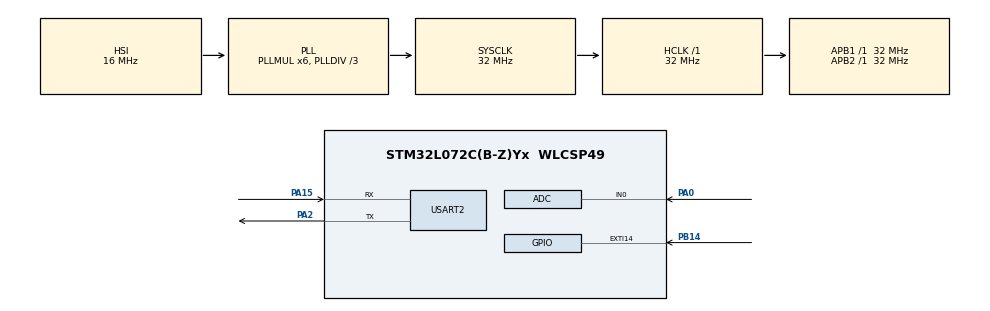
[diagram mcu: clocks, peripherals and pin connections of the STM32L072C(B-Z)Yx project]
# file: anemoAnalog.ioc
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ADC.ContinuousConvMode=ENABLE
ADC.SamplingTime=ADC_SAMPLETIME_79CYCLES_5
Dma.ADC.0.Direction=DMA_PERIPH_TO_MEMORY
Dma.ADC.0.Instance=DMA1_Channel1
Dma.ADC.0.MemDataAlignment=DMA_MDATAALIGN_HALFWORD
Dma.ADC.0.MemInc=DMA_MINC_ENABLE
Dma.ADC.0.Mode=DMA_CIRCULAR
Dma.ADC.0.PeriphDataAlignment=DMA_PDATAALIGN_HALFWORD
Dma.ADC.0.PeriphInc=DMA_PINC_DISABLE
Dma.ADC.0.Priority=DMA_PRIORITY_LOW
Dma.Request0=ADC
Mcu.Family=STM32L0
Mcu.Name=STM32L072C(B-Z)Yx
Mcu.Package=WLCSP49
NVIC.DMA1_Channel1_IRQn=true\:0\:0\:false\:false\:true\:false\:true\:true
NVIC.EXTI4_15_IRQn=true\:0\:0\:false\:false\:true\:true\:true\:true
PA0.Mode=IN0
PA0.Signal=ADC_IN0
PA15.GPIO_Speed=GPIO_SPEED_FREQ_HIGH
PA15.Mode=Asynchronous
PA15.Signal=USART2_RX
PA2.GPIO_Speed=GPIO_SPEED_FREQ_HIGH
PA2.Mode=Asynchronous
PA2.Signal=USART2_TX
PB14.GPIO_ModeDefaultEXTI=GPIO_MODE_IT_RISING_FALLING
PB14.Signal=GPXTI14
ProjectManager.HeapSize=0x200
ProjectManager.StackSize=0x400
ProjectManager.TargetToolchain=STM32CubeIDE
RCC.AHBFreq_Value=32000000
RCC.APB1Freq_Value=32000000
RCC.APB1TimFreq_Value=32000000
RCC.APB2Freq_Value=32000000
RCC.APB2TimFreq_Value=32000000
RCC.HCLKFreq_Value=32000000
RCC.HSE_VALUE=8000000
RCC.HSI16_VALUE=16000000
RCC.HSI48_VALUE=48000000
RCC.HSI_VALUE=16000000
RCC.LSE_VALUE=32768
RCC.MSI_VALUE=2097000
RCC.PLLDIV=RCC_PLLDIV_3
RCC.PLLMUL=RCC_PLLMUL_6
RCC.SYSCLKFreq_VALUE=32000000
RCC.SYSCLKSource=RCC_SYSCLKSOURCE_PLLCLK
RCC.VCOOutputFreq_Value=96000000
USART2.VirtualMode-Asynchronous=VM_ASYNC
board=B-L072Z-LRWAN1

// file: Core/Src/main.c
/* USER CODE BEGIN Header */
/**
  ******************************************************************************
  * @file           : main.c
  * @brief          : Main program body
  ******************************************************************************
  * @attention
  *
  * Copyright (c) 2024 STMicroelectronics.
  * All rights reserved.
  *
  * This software is licensed under terms that can be found in the LICENSE file
  * in the root directory of this software component.
  * If no LICENSE file comes with this software, it is provided AS-IS.
  *
  ******************************************************************************
  */
/* USER CODE END Header */
#include "main.h"
#include "stdio.h"

ADC_HandleTypeDef hadc;
DMA_HandleTypeDef hdma_adc;

UART_HandleTypeDef huart2;

/* USER CODE BEGIN PV */
uint32_t direction;

char readval[150];

/* USER CODE END PV */

void SystemClock_Config(void);
static void MX_GPIO_Init(void);
static void MX_DMA_Init(void);
static void MX_ADC_Init(void);
static void MX_USART2_UART_Init(void);

int main(void)
{

  /* MCU Configuration--------------------------------------------------------*/

  /* Reset of all peripherals, Initializes the Flash interface and the Systick. */
  HAL_Init();

  /* Configure the system clock */
  SystemClock_Config();

  /* Initialize all configured peripherals */
  MX_GPIO_Init();
  MX_DMA_Init();
  MX_ADC_Init();
  MX_USART2_UART_Init();
  /* USER CODE BEGIN 2 */
HAL_ADCEx_Calibration_Start(&hadc, ADC_SINGLE_ENDED);
HAL_ADC_Start_DMA(&hadc,(uint32_t*)&direction,1);
  /* USER CODE END 2 */

  /* Infinite loop */
  /* USER CODE BEGIN WHILE */
  while (1)
  {   HAL_ADC_Start(&hadc);
	  HAL_ADC_PollForConversion(&hadc,1000);
	  	direction= HAL_ADC_GetValue(&hadc);
	  	sprintf(readval,"val: %lu\r\n",direction);
	  	HAL_UART_Transmit(&huart2,(uint8_t *)readval,sizeof(readval),HAL_MAX_DELAY);
	  	HAL_Delay(1000);

    /* USER CODE END WHILE */

  }
}

void SystemClock_Config(void)
{
  RCC_OscInitTypeDef RCC_OscInitStruct = {0};
  RCC_ClkInitTypeDef RCC_ClkInitStruct = {0};
  RCC_PeriphCLKInitTypeDef PeriphClkInit = {0};

  /** Configure the main internal regulator output voltage
  */
  __HAL_PWR_VOLTAGESCALING_CONFIG(PWR_REGULATOR_VOLTAGE_SCALE1);

  /** Initializes the RCC Oscillators according to the specified parameters
  * in the RCC_OscInitTypeDef structure.
  */
  RCC_OscInitStruct.OscillatorType = RCC_OSCILLATORTYPE_HSI;
  RCC_OscInitStruct.HSIState = RCC_HSI_ON;
  RCC_OscInitStruct.HSICalibrationValue = RCC_HSICALIBRATION_DEFAULT;
  RCC_OscInitStruct.PLL.PLLState = RCC_PLL_ON;
  RCC_OscInitStruct.PLL.PLLSource = RCC_PLLSOURCE_HSI;
  RCC_OscInitStruct.PLL.PLLMUL = RCC_PLLMUL_6;
  RCC_OscInitStruct.PLL.PLLDIV = RCC_PLLDIV_3;
  if (HAL_RCC_OscConfig(&RCC_OscInitStruct) != HAL_OK)
  {
    Error_Handler();
  }

  /** Initializes the CPU, AHB and APB buses clocks
  */
  RCC_ClkInitStruct.ClockType = RCC_CLOCKTYPE_HCLK|RCC_CLOCKTYPE_SYSCLK
                              |RCC_CLOCKTYPE_PCLK1|RCC_CLOCKTYPE_PCLK2;
  RCC_ClkInitStruct.SYSCLKSource = RCC_SYSCLKSOURCE_PLLCLK;
  RCC_ClkInitStruct.AHBCLKDivider = RCC_SYSCLK_DIV1;
  RCC_ClkInitStruct.APB1CLKDivider = RCC_HCLK_DIV1;
  RCC_ClkInitStruct.APB2CLKDivider = RCC_HCLK_DIV1;

  if (HAL_RCC_ClockConfig(&RCC_ClkInitStruct, FLASH_LATENCY_1) != HAL_OK)
  {
    Error_Handler();
  }
  PeriphClkInit.PeriphClockSelection = RCC_PERIPHCLK_USART2;
  PeriphClkInit.Usart2ClockSelection = RCC_USART2CLKSOURCE_PCLK1;
  if (HAL_RCCEx_PeriphCLKConfig(&PeriphClkInit) != HAL_OK)
  {
    Error_Handler();
  }
}

static void MX_ADC_Init(void)
{

  ADC_ChannelConfTypeDef sConfig = {0};

  /** Configure the global features of the ADC (Clock, Resolution, Data Alignment and number of conversion)
  */
  hadc.Instance = ADC1;
  hadc.Init.OversamplingMode = DISABLE;
  hadc.Init.ClockPrescaler = ADC_CLOCK_SYNC_PCLK_DIV2;
  hadc.Init.Resolution = ADC_RESOLUTION_12B;
  hadc.Init.SamplingTime = ADC_SAMPLETIME_79CYCLES_5;
  hadc.Init.ScanConvMode = ADC_SCAN_DIRECTION_FORWARD;
  hadc.Init.DataAlign = ADC_DATAALIGN_RIGHT;
  hadc.Init.ContinuousConvMode = ENABLE;
  hadc.Init.DiscontinuousConvMode = DISABLE;
  hadc.Init.ExternalTrigConvEdge = ADC_EXTERNALTRIGCONVEDGE_NONE;
  hadc.Init.ExternalTrigConv = ADC_SOFTWARE_START;
  hadc.Init.DMAContinuousRequests = DISABLE;
  hadc.Init.EOCSelection = ADC_EOC_SINGLE_CONV;
  hadc.Init.Overrun = ADC_OVR_DATA_PRESERVED;
  hadc.Init.LowPowerAutoWait = DISABLE;
  hadc.Init.LowPowerFrequencyMode = DISABLE;
  hadc.Init.LowPowerAutoPowerOff = DISABLE;
  if (HAL_ADC_Init(&hadc) != HAL_OK)
  {
    Error_Handler();
  }

  /** Configure for the selected ADC regular channel to be converted.
  */
  sConfig.Channel = ADC_CHANNEL_0;
  sConfig.Rank = ADC_RANK_CHANNEL_NUMBER;
  if (HAL_ADC_ConfigChannel(&hadc, &sConfig) != HAL_OK)
  {
    Error_Handler();
  }

}

static void MX_USART2_UART_Init(void)
{

  huart2.Instance = USART2;
  huart2.Init.BaudRate = 115200;
  huart2.Init.WordLength = UART_WORDLENGTH_8B;
  huart2.Init.StopBits = UART_STOPBITS_1;
  huart2.Init.Parity = UART_PARITY_NONE;
  huart2.Init.Mode = UART_MODE_TX_RX;
  huart2.Init.HwFlowCtl = UART_HWCONTROL_NONE;
  huart2.Init.OverSampling = UART_OVERSAMPLING_16;
  huart2.Init.OneBitSampling = UART_ONE_BIT_SAMPLE_DISABLE;
  huart2.AdvancedInit.AdvFeatureInit = UART_ADVFEATURE_NO_INIT;
  if (HAL_UART_Init(&huart2) != HAL_OK)
  {
    Error_Handler();
  }

}

static void MX_DMA_Init(void)
{

  /* DMA controller clock enable */
  __HAL_RCC_DMA1_CLK_ENABLE();

  /* DMA interrupt init */
  /* DMA1_Channel1_IRQn interrupt configuration */
  HAL_NVIC_SetPriority(DMA1_Channel1_IRQn, 0, 0);
  HAL_NVIC_EnableIRQ(DMA1_Channel1_IRQn);

}

static void MX_GPIO_Init(void)
{
  GPIO_InitTypeDef GPIO_InitStruct = {0};

  /* GPIO Ports Clock Enable */
  __HAL_RCC_GPIOA_CLK_ENABLE();
  __HAL_RCC_GPIOB_CLK_ENABLE();

  /*Configure GPIO pin : PB14 */
  GPIO_InitStruct.Pin = GPIO_PIN_14;
  GPIO_InitStruct.Mode = GPIO_MODE_IT_RISING_FALLING;
  GPIO_InitStruct.Pull = GPIO_NOPULL;
  HAL_GPIO_Init(GPIOB, &GPIO_InitStruct);

  /* EXTI interrupt init*/
  HAL_NVIC_SetPriority(EXTI4_15_IRQn, 0, 0);
  HAL_NVIC_EnableIRQ(EXTI4_15_IRQn);

}

void Error_Handler(void)
{
  __disable_irq();
  while (1)
  {
  }
}
